# APM32F445 register map
File version: 1.0
CPU: CM4 r0p1, little endian, MPU, FPU, 4 interrupt priority bits
Registers are 32-bit, read-write, reset 0x0 unless marked. A register's access mark holds for its fields unless they carry their own. Offsets are from the block's base; [hi:lo] are bit positions; {n}, {i} and the like mark numbered series.

## FLASH — Flash Memory
Base 0x40020000
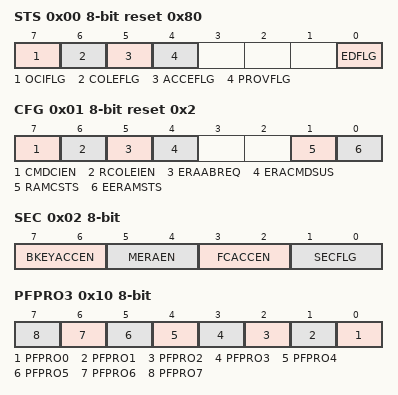
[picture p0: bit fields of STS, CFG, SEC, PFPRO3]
0x00 STS 8-bit reset 0x80 — Status Register
  [7] OCIFLG — Operation Completed Interrupt Flag
  [6] COLEFLG — Collision Error Flag
    0=No collision error detected; 1=Collision error detected
  [5] ACCEFLG — Access Error Flag
    0=No access error detected; 1=Access error detected
  [4] PROVFLG — Protection Violation Flag
    0=No protection violation detected; 1=Protection violation detected
  [0] EDFLG ro — Error Detect Flag
0x01 CFG 8-bit reset 0x2 — Configure Register
  [7] CMDCIEN — Command Complete Interrupt Enable
    0=Command complete interrupt disabled; 1=Command complete interrupt enabled. An interrupt request is generated whenever the STS[OCIFLG] flag is set.
  [6] RCOLEIEN — Read Collision Error Interrupt Enable
    0=Read collision error interrupt disabled; 1=Read collision error interrupt enabled. An interrupt request is generated whenever an FLASH read collision error is detected (see the description of STS[COLEFLG]).
  [5] ERAABREQ ro — Erase All Blocks Request
    0=No request or request complete
  [4] ERACMDSUS — Erase Command Suspend
    0=No suspend requested; 1=Suspend the current Erase Flash Sector command execution
  [1] RAMCSTS ro — CFGRAM Current State
  [0] EERAMSTS ro — EERAM State, RAM Available for EEPROM
0x02 SEC 8-bit ro reset not defined — Security Register
  [7:6] BKEYACCEN — Backdoor Key Access Enable
    0=Backdoor key access disabled; 1=Backdoor key access disabled (preferred BKEYACCEN state to disable backdoor key access); 2=Backdoor key access enabled; 3=Backdoor key access disabled
  [5:4] MERAEN — Mass Erase Enable
    0=Mass erase is enabled; 1=Mass erase is enabled; 3=Mass erase is enabled
  [3:2] FCACCEN — Flash Content Access Enable
    0=Factory access granted; 3=Factory access granted
  [1:0] SECFLG — Flash Secure Flag
    2=MCU security status is unsecure (The standard shipping condition of the FLASH is unsecure.)
0x03 NOPT 8-bit ro reset not defined — Nonvolatile Option Register
  [7:0] NOPT — Nonvolatile Option
0x04 CCMDDATA3 8-bit — Common Command Data Registers 3
  [7:0] PCMDCODEP3 — Provide Command Code and Parameter
0x05 CCMDDATA2 8-bit — Common Command Data Registers 2
  [7:0] PCMDCODEP2 — Provide Command Code and Parameter
0x06 CCMDDATA1 8-bit — Common Command Data Registers 1
  [7:0] PCMDCODEP1 — Provide Command Code and Parameter
0x07 CCMDDATA0 8-bit — Common Command Data Registers 0
  [7:0] PCMDCODEP0 — Provide Command Code and Parameter
0x08 CCMDDATA7 8-bit — Common Command Data Registers 7
  [7:0] PCMDCODEP7 — Provide Command Code and Parameter
0x09 CCMDDATA6 8-bit — Common Command Data Registers 6
  [7:0] PCMDCODEP6 — Provide Command Code and Parameter
0x0A CCMDDATA5 8-bit — Common Command Data Registers 5
  [7:0] PCMDCODEP5 — Provide Command Code and Parameter
0x0B CCMDDATA4 8-bit — Common Command Data Registers 4
  [7:0] PCMDCODEP4 — Provide Command Code and Parameter
0x0C CCMDDATAB 8-bit — Common Command Data Registers B
  [7:0] PCMDCODEPB — Provide Command Code and Parameter
0x0D CCMDDATAA 8-bit — Common Command Data Registers A
  [7:0] PCMDCODEPA — Provide Command Code and Parameter
0x0E CCMDDATA9 8-bit — Common Command Data Registers 9
  [7:0] PCMDCODEP9 — Provide Command Code and Parameter
0x0F CCMDDATA8 8-bit — Common Command Data Registers 8
  [7:0] PCMDCODEP8 — Provide Command Code and Parameter
0x10 PFPRO3 8-bit reset not defined — Program Flash Protect Register 3
  [n] PFPRO{n} (n=0..7) — Program Flash Protect Area {n}
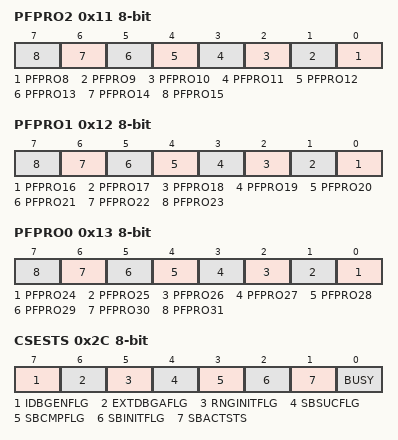
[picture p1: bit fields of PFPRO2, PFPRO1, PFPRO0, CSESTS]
0x11 PFPRO2 8-bit reset not defined — Program Flash Protect Register 2
  [n-8] PFPRO{n} (n=8..15) — Program Flash Protect Area {n}
0x12 PFPRO1 8-bit reset not defined — Program Flash Protect Register 1
  [n-16] PFPRO{n} (n=16..23) — Program Flash Protect Area {n}
0x13 PFPRO0 8-bit reset not defined — Program Flash Protect Register 0
  [n-24] PFPRO{n} (n=24..31) — Program Flash Protect Area {n}
0x16 EEPRO 8-bit reset not defined — EEPROM Protect Register
  [7:0] EEPRO — EEPROM Protect
0x17 DFPRO 8-bit reset not defined — Data Flash Protect Register
  [7:0] DFPRO — Data Flash Protect
    0=Data Flash region is protected; 1=Data Flash region is not protected
0x2C CSESTS 8-bit ro — CSE Status Register
  [7] IDBGENFLG — Internal Debug Enable Flag
  [6] EXTDBGAFLG — External Debug Attached Flag
  [5] RNGINITFLG — Random Number Generator Initialized Flag
  [4] SBSUCFLG — Secure Boot Successful Flag
  [3] SBCMPFLG — Secure Boot Complete Flag
  [2] SBINITFLG — Secure Boot Initialization Completed flag
  [1] SBACTSTS — Secure Boot Activated Status
  [0] BUSY
0x2E ESTS 8-bit — Error Status Register
  [1] DBFIFLG — Double Bit Fault Interrupt Flag
    0=Double bit fault not detected during a valid flash read access from the platform flash controller; 1=Double bit fault detected (or ECFG[EDBFINTD] is set) during a valid flash read access from the platform flash controller
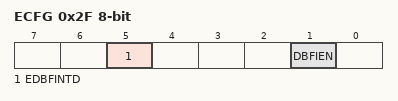
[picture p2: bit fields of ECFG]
0x2F ECFG 8-bit — Error Configuration Register
  [5] EDBFINTD — Emulate Double Bit Fault Interrupt Detect
    0=ESTS[DBFIFLG] sets only if a double bit fault is detected during read access from the platform flash controller; 1=ESTS[DBFIFLG] sets during any valid flash read access from the platform flash controller. An interrupt request is generated if the DBFIEN bit is set.
  [1] DBFIEN — Double Bit Fault Interrupt Enable
    0=Double bit fault detect interrupt disabled; 1=Double bit fault detect interrupt enabled. An interrupt request is generated whenever the ESTS[DBFIFLG] flag is set.
